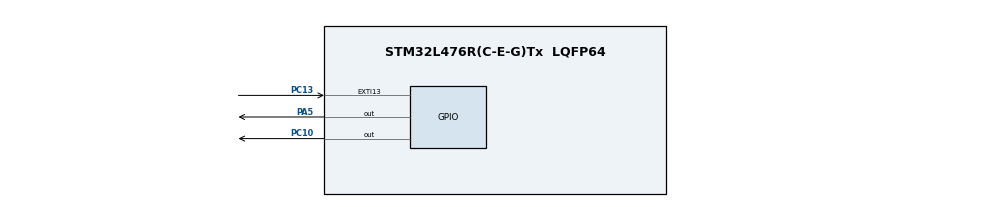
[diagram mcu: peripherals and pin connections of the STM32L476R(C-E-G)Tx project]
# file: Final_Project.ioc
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Mcu.Family=STM32L4
Mcu.Name=STM32L476R(C-E-G)Tx
Mcu.Package=LQFP64
NVIC.EXTI15_10_IRQn=true\:1\:0\:true\:false\:true\:true\:true
NVIC.PriorityGroup=NVIC_PRIORITYGROUP_4
PA5.Signal=GPIO_Output
PC10.Signal=GPIO_Output
PC13.GPIO_ModeDefaultEXTI=GPIO_MODE_IT_FALLING
PC13.Signal=GPXTI13
ProjectManager.HeapSize=0x200
ProjectManager.StackSize=0x400
ProjectManager.TargetToolchain=STM32CubeIDE
RCC.ADCFreq_Value=96000000
RCC.AHBFreq_Value=24000000
RCC.APB1Freq_Value=24000000
RCC.APB1TimFreq_Value=24000000
RCC.APB2Freq_Value=24000000
RCC.APB2TimFreq_Value=24000000
RCC.CortexFreq_Value=24000000
RCC.HCLKFreq_Value=24000000
RCC.HSE_VALUE=8000000
RCC.HSI_VALUE=16000000
RCC.LSE_VALUE=32768
RCC.MSIClockRange=RCC_MSIRANGE_9
RCC.MSI_VALUE=24000000
RCC.SYSCLKFreq_VALUE=24000000
RCC.USBFreq_Value=96000000
RCC.VCOOutputFreq_Value=192000000
VP_RTC_VS_RTC_Activate.Mode=RTC_Enabled
VP_RTC_VS_RTC_Calendar.Mode=RTC_Calendar
board=custom

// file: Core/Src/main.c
/* USER CODE BEGIN Header */
/**
  ******************************************************************************
  * @file           : main.c
  * @brief          : Main program body
  ******************************************************************************
  * @attention
  *
  * <h2><center>&copy; Copyright (c) 2020 STMicroelectronics.
  * All rights reserved.</center></h2>
  *
  * This software component is licensed by ST under BSD 3-Clause license,
  * the "License"; You may not use this file except in compliance with the
  * License. You may obtain a copy of the License at:
  *                        opensource.org/licenses/BSD-3-Clause
  *
  ******************************************************************************
  */
/* USER CODE END Header */
#include "main.h"
#include "rtc.h"
#include "gpio.h"

/* USER CODE BEGIN Includes */
#include "stdbool.h"
/* USER CODE END Includes */

/* USER CODE BEGIN PTD */
//Type d'actions pouvant être effectuées à l'activation du blue mode
typedef enum
{
	BLUE_MODE_ACTIVATE_SLEEP,        /*< Activation du sleep lors du passage en blue mode. */
	BLUE_MODE_ACTIVATE_CALIBRATION,  /*< Activation de la calibration lors du passage en blue mode. */
	BLUE_MODE_ACTIVATE_STOP,		 /*< Activation du stop lors du passage en blue mode. */
}blue_mode_t;
/* USER CODE END PTD */

/* USER CODE BEGIN PD */
//Configurations des clocks
#define CK_CONFIG_PLL_80MGHZ 0		/*< Configuration clock experience 1 (PLL 80MHz; MSI 4 MGHz). */
#define CK_CONFIG_MSI_24MGHZ 1		/*< Configuration clock autres experiences (MSI 24 MHz). */

//Configuration de la calibration
#define CALIBRATION_OFF 0			/*< calbration off en normal mode. */
#define CALIBRATION_ON 1			/*< calbration on en normal mode. */

//Configuration du sleep
#define SLEEP_OFF 0					/*< sleep(100Hz) off en normal mode. */
#define SLEEP_ON 1					/*< sleep(100Hz) on en normal mode. */

//Mode de fonctionnement du système
#define NORMAL_MODE 0				/*< mode normal. */
#define BLUE_MODE 1					/*< blue mode. */
/* USER CODE END PD */

/* USER CODE BEGIN PV */
int expe=1; 						/*< Numéro de l'expérience en cours. */
int compteur_systick=0;				/*< Compteur permettant de compter via l'interruption systick (pour le clignotement de la LED). */
int mode=NORMAL_MODE;				/*< Initialisation mode de fonctionnement en "normal". */
blue_mode_t blue_mode_action;		/*< Action à effectuer lors du blue mode. */
/* USER CODE END PV */

void SystemClock_Config(bool ck_config, uint32_t flash_latency,uint32_t voltage_scaling,bool calibration); //Fonction d'initialisation des clocks.
/* USER CODE BEGIN PFP */
void Systick_Init (void);                                      /*<Initialisation de systick. */
void LSE_Init(void);										   /*<Initialisation du LSE. */
void PLL_Activate(void);									   /*<Activation de la PLL. */
void PLL_Disable(void);                                        /*<Désactivation de la PLL. */
void RTC_wakeup_init_from_standby_or_shutdown( int delay );	   /*<Initialisation du réveil du mode shutdown. */
void RTC_wakeup_init_from_stop( int delay );                   /*<Initialisation du réveil des modes stop. */
/* USER CODE END PFP */

int main(void)
{
  /* USER CODE BEGIN 1 */
  //Paramètres des experiences
  bool ck_config;							/*< Configuration de la clock. */
  uint32_t flash_latency;                   /*< Configuration de la flash latency. */
  uint32_t voltage_scaling;					/*< Configuration du voltage scaling */
  bool calibration;							/*< Configuration calibration*/
  bool sleep;							    /*< Configuration du sleep */
  uint32_t stop;							/*< Configuration du "niveau de stp" (exp. 5 à 8) */
  /* USER CODE END 1 */

  /* MCU Configuration--------------------------------------------------------*/

  /* Reset of all peripherals, Initializes the Flash interface and the Systick. */

  LL_APB2_GRP1_EnableClock(LL_APB2_GRP1_PERIPH_SYSCFG);
  LL_APB1_GRP1_EnableClock(LL_APB1_GRP1_PERIPH_PWR);

  NVIC_SetPriorityGrouping(NVIC_PRIORITYGROUP_4);

  /* System interrupt init*/

  /* USER CODE BEGIN Init */
  //Initialisation LSE et RTC uniquement lors d'un démarrage à froid
  if(LL_RCC_LSE_IsReady() != 1)
     {
   	  LSE_Init();
   	  MX_RTC_Init();
     }

  //Récupération expe dans Bckup domain et incrémentation
   LL_APB1_GRP1_EnableClock( LL_APB1_GRP1_PERIPH_PWR );
   LL_PWR_EnableBkUpAccess();
   LL_RTC_DisableWriteProtection(RTC);
   expe=LL_RTC_BAK_GetRegister(RTC, 0)+1;
   if (expe==9)
   {
	   expe=1;
	   LL_RTC_BAK_SetRegister(RTC, 0, 0);
   }
   else
   {
	   LL_RTC_BAK_SetRegister(RTC, 0, expe);
   }
   LL_RTC_EnableWriteProtection(RTC);

  //Définition des paramètres de chaque experience selon la valeur de expe
    switch(expe)
    {
    case 1:
  	  ck_config=CK_CONFIG_PLL_80MGHZ;
  	  flash_latency=LL_FLASH_LATENCY_4;
  	  voltage_scaling=LL_PWR_REGU_VOLTAGE_SCALE1;
  	  calibration=CALIBRATION_OFF;
  	  sleep=SLEEP_OFF;
  	  blue_mode_action=BLUE_MODE_ACTIVATE_SLEEP;
  	  break;
    case 2:
  	  ck_config=CK_CONFIG_MSI_24MGHZ;
  	  flash_latency=LL_FLASH_LATENCY_1;
  	  voltage_scaling=LL_PWR_REGU_VOLTAGE_SCALE1;
  	  calibration=CALIBRATION_OFF;
  	  sleep=SLEEP_OFF;
  	  blue_mode_action=BLUE_MODE_ACTIVATE_CALIBRATION;
  	  break;
    case 3:
      ck_config=CK_CONFIG_MSI_24MGHZ;
      flash_latency=LL_FLASH_LATENCY_3;
      voltage_scaling=LL_PWR_REGU_VOLTAGE_SCALE2;
      calibration=CALIBRATION_OFF;
      sleep=SLEEP_OFF;
      blue_mode_action=BLUE_MODE_ACTIVATE_SLEEP;
      break;
    case 4:
      ck_config=CK_CONFIG_MSI_24MGHZ;
      flash_latency=LL_FLASH_LATENCY_3;
      voltage_scaling=LL_PWR_REGU_VOLTAGE_SCALE2;
      calibration=CALIBRATION_OFF;
      sleep=SLEEP_OFF;
      blue_mode_action=BLUE_MODE_ACTIVATE_CALIBRATION;
      break;
    case 5:
  	  ck_config=CK_CONFIG_MSI_24MGHZ;
  	  flash_latency=LL_FLASH_LATENCY_3;
  	  voltage_scaling=LL_PWR_REGU_VOLTAGE_SCALE2;
  	  calibration=CALIBRATION_ON;
  	  sleep=SLEEP_ON;
  	  stop=LL_PWR_MODE_STOP0;
  	  blue_mode_action=BLUE_MODE_ACTIVATE_STOP;
  	  break;
    case 6:
      ck_config=CK_CONFIG_MSI_24MGHZ;
      flash_latency=LL_FLASH_LATENCY_3;
  	  voltage_scaling=LL_PWR_REGU_VOLTAGE_SCALE2;
  	  calibration=CALIBRATION_ON;
      sleep=SLEEP_ON;
   	  stop=LL_PWR_MODE_STOP1;
   	  blue_mode_action=BLUE_MODE_ACTIVATE_STOP;
   	  break;
    case 7:
      ck_config=CK_CONFIG_MSI_24MGHZ;
      flash_latency=LL_FLASH_LATENCY_3;
      voltage_scaling=LL_PWR_REGU_VOLTAGE_SCALE2;
      calibration=CALIBRATION_ON;
      sleep=SLEEP_ON;
      stop=LL_PWR_MODE_STOP2;
      blue_mode_action=BLUE_MODE_ACTIVATE_STOP;
      break;
    case 8:
      ck_config=CK_CONFIG_MSI_24MGHZ;
      flash_latency=LL_FLASH_LATENCY_3;
      voltage_scaling=LL_PWR_REGU_VOLTAGE_SCALE2;
  	  calibration=CALIBRATION_ON;
      sleep=SLEEP_ON;
      stop=LL_PWR_MODE_SHUTDOWN;
   	  blue_mode_action=BLUE_MODE_ACTIVATE_STOP;
   	  break;
    }
  /* USER CODE END Init */

  /* Configure the system clock */
  SystemClock_Config(ck_config,flash_latency,voltage_scaling,calibration);

  /* USER CODE BEGIN SysInit */
  //Initialisation systick
  Systick_Init ();
  /* USER CODE END SysInit */

  /* Initialize all configured peripherals */
  MX_GPIO_Init();

  /* Infinite loop */
  while (1)
  {

    /* USER CODE BEGIN 3 */
	  //Activation du sleep en blue mode OU lorsque le sleep est activé en normal mode (exp. 5 à8)
	  if (((sleep==SLEEP_ON)&&(mode==NORMAL_MODE))||((mode==BLUE_MODE)&&(blue_mode_action==BLUE_MODE_ACTIVATE_SLEEP)))
	    {
		  LL_LPM_EnableSleep();
		  __WFI();
	    }
	  //Activation du stop en blue mode
	  if ((mode==BLUE_MODE)&&(blue_mode_action==BLUE_MODE_ACTIVATE_STOP))
	  	{
		  	mode=NORMAL_MODE;
	  		LL_PWR_SetPowerMode(stop);
	  		if (stop==LL_PWR_MODE_SHUTDOWN) //cas shutdown (exp 8)
	  			RTC_wakeup_init_from_standby_or_shutdown(10);
	  		else //cas stop (exp 5 à 8)
	  			RTC_wakeup_init_from_stop(10);

	  		LL_LPM_EnableDeepSleep();
	  		__WFI();
	  	}
  }
  /* USER CODE END 3 */
}

void SystemClock_Config(bool ck_config, uint32_t flash_latency,uint32_t voltage_scaling,bool calibration)
{
  //Gestion flash latency et voltage scaling
  LL_FLASH_SetLatency(flash_latency);
  while(LL_FLASH_GetLatency()!= flash_latency)
  {
  }
  LL_PWR_SetRegulVoltageScaling(voltage_scaling);
  LL_RCC_MSI_Enable();

   /* Wait till MSI is ready */
  while(LL_RCC_MSI_IsReady() != 1)
  {

  }
  LL_RCC_MSI_EnableRangeSelection();
  //Gestion fréquence de clock et PLL
    if(ck_config==CK_CONFIG_MSI_24MGHZ){ //Cas MSI à 24MHz sans PLL
  	  LL_RCC_MSI_SetRange(LL_RCC_MSIRANGE_9);
  	 /* Wait till System clock is ready */
  	  while(LL_RCC_GetSysClkSource() != LL_RCC_SYS_CLKSOURCE_STATUS_MSI)
  	  {

  	  }
  	  LL_RCC_SetAHBPrescaler(LL_RCC_SYSCLK_DIV_1);
  	  LL_RCC_SetAPB1Prescaler(LL_RCC_APB1_DIV_1);
  	  LL_RCC_SetAPB2Prescaler(LL_RCC_APB2_DIV_1);

  	  LL_Init1msTick(24000000);

  	  LL_SetSystemCoreClock(24000000);
    }else{								//Cas MSI 4Mhz et PLL à 80MHz
  	  LL_RCC_MSI_SetRange(LL_RCC_MSIRANGE_6);
  	  LL_RCC_MSI_SetCalibTrimming(0);
  	  LL_RCC_PLL_ConfigDomain_SYS(LL_RCC_PLLSOURCE_MSI, LL_RCC_PLLM_DIV_1, 40, LL_RCC_PLLR_DIV_2);
  	  LL_RCC_PLL_EnableDomain_SYS();
  	  LL_RCC_PLL_Enable();
  	/* Wait till PLL is ready */
  	  while(LL_RCC_PLL_IsReady() != 1)
  	  {

  	  }
  	  LL_RCC_SetSysClkSource(LL_RCC_SYS_CLKSOURCE_PLL);

  	   /* Wait till System clock is ready */
  	  while(LL_RCC_GetSysClkSource() != LL_RCC_SYS_CLKSOURCE_STATUS_PLL)
  	  {

  	  }
  	  LL_RCC_SetAHBPrescaler(LL_RCC_SYSCLK_DIV_1);
  	  LL_RCC_SetAPB1Prescaler(LL_RCC_APB1_DIV_1);
  	  LL_RCC_SetAPB2Prescaler(LL_RCC_APB2_DIV_1);

  	  LL_Init1msTick(80000000);

  	  LL_SetSystemCoreClock(80000000);
    }
    //Gestion Calibration
    if(calibration==CALIBRATION_ON){
    	PLL_Activate();
    }
    else{
    	PLL_Disable();
    }
}

/* USER CODE BEGIN 4 */
void Systick_Init (void)
{
	int clock=0;
	SysTick->CTRL |= (1<<2);
	SysTick->CTRL |= (1<<1);
	SystemCoreClockUpdate();
	clock=SystemCoreClock/100;
	SysTick->LOAD = clock;//SystemCoreClock/100;
	SysTick->VAL=0;
	NVIC_SetPriority(-1,0);
	SysTick->CTRL |= (1<<0);
}

void LSE_Init(void)
{
	  LL_APB1_GRP1_EnableClock( LL_APB1_GRP1_PERIPH_PWR );
	  LL_PWR_EnableBkUpAccess();
	    /* Wait till LSE is ready */
	   if(LL_RCC_LSE_IsReady() != 1)
	   {
		   LL_RCC_ForceBackupDomainReset();
		   LL_RCC_ReleaseBackupDomainReset();
		   LL_RCC_LSE_SetDriveCapability(LL_RCC_LSEDRIVE_LOW);
		   LL_RCC_LSE_Enable();
		   while (LL_RCC_LSE_IsReady() != 1)
		   {

		   }
		   LL_RCC_SetRTCClockSource(LL_RCC_RTC_CLKSOURCE_LSE);
	   }
}

void SysTick_Handler(void)
//Interruption de systick (50Hz)
{
  compteur_systick++;
  if (compteur_systick==200) //clignotement de la LED tte les 2s
  {
	  LL_GPIO_TogglePin(GPIOA, LL_GPIO_PIN_5);
  }
  else if (compteur_systick==(200+expe*50)) //Durée d'impulsion dépendant de expe
  {
	  LL_GPIO_TogglePin(GPIOA, LL_GPIO_PIN_5);
	  compteur_systick=0;
  }
  LL_GPIO_TogglePin(GPIOC, LL_GPIO_PIN_10); //Génération signal carré sur PC10
}

void EXTI15_10_IRQHandler(void)
//Interruption bouton blue mode
{
  /* USER CODE BEGIN EXTI15_10_IRQn 0 */

  /* USER CODE END EXTI15_10_IRQn 0 */
  if (LL_EXTI_IsActiveFlag_0_31(LL_EXTI_LINE_13) != RESET)
  {
    LL_EXTI_ClearFlag_0_31(LL_EXTI_LINE_13);
    /* USER CODE BEGIN LL_EXTI_LINE_13 */
    mode=BLUE_MODE; //Passage en blue mode + gestion passage en calibration ON
    if (blue_mode_action==BLUE_MODE_ACTIVATE_CALIBRATION)
    {
    	PLL_Activate();
    }
    /* USER CODE END LL_EXTI_LINE_13 */
  }
  /* USER CODE BEGIN EXTI15_10_IRQn 1 */

  /* USER CODE END EXTI15_10_IRQn 1 */
}

void PLL_Activate(void)
{
	LL_RCC_MSI_EnablePLLMode();
	while(LL_RCC_MSI_IsReady() != 1)
   {

	}
	LL_RCC_MSI_SetCalibTrimming(0);
	LL_RCC_SetSysClkSource(LL_RCC_SYS_CLKSOURCE_MSI);
}

void PLL_Disable(void)
{
	LL_RCC_MSI_DisablePLLMode();
}
// partie commune a toutes les utilisations du wakeup timer
static void RTC_wakeup_init( int delay )
{
LL_RTC_DisableWriteProtection( RTC );
LL_RTC_WAKEUP_Disable( RTC );
while	( !LL_RTC_IsActiveFlag_WUTW( RTC ) )
	{ }
// connecter le timer a l'horloge 1Hz de la RTC
LL_RTC_WAKEUP_SetClock( RTC, LL_RTC_WAKEUPCLOCK_CKSPRE );
// fixer la duree de temporisation
LL_RTC_WAKEUP_SetAutoReload( RTC, delay );	// 16 bits
LL_RTC_ClearFlag_WUT(RTC);
LL_RTC_EnableIT_WUT(RTC);
LL_RTC_WAKEUP_Enable(RTC);
LL_RTC_EnableWriteProtection(RTC);
}

// Dans le cas des modes STANDBY et SHUTDOWN, le MPU sera reveille par reset
// causé par 1 wakeup line (interne ou externe) (le NVIC n'est plus alimenté)
void RTC_wakeup_init_from_standby_or_shutdown( int delay )
{
RTC_wakeup_init( delay );
// enable the Internal Wake-up line
LL_PWR_EnableInternWU();	// ceci ne concerne que Standby et Shutdown, pas STOPx
}

// Dans le cas des modes STOPx, le MPU sera reveille par interruption
// le module EXTI et une partie du NVIC sont encore alimentes
// le contenu de la RAM et des registres étant préservé, le MPU
// reprend l'execution après l'instruction WFI
void RTC_wakeup_init_from_stop( int delay )
{
RTC_wakeup_init( delay );
// valider l'interrupt par la ligne 20 du module EXTI, qui est réservée au wakeup timer
LL_EXTI_EnableIT_0_31( LL_EXTI_LINE_20 );
LL_EXTI_EnableRisingTrig_0_31( LL_EXTI_LINE_20 );
// valider l'interrupt chez NVIC
NVIC_SetPriority( RTC_WKUP_IRQn, 1 );
NVIC_EnableIRQ( RTC_WKUP_IRQn );
}

// wakeup timer interrupt Handler (inutile mais doit etre defini)
void RTC_WKUP_IRQHandler()
{
LL_EXTI_ClearFlag_0_31( LL_EXTI_LINE_20 );
}
/* USER CODE END 4 */

void Error_Handler(void)
{
}

/************************ (C) COPYRIGHT STMicroelectronics *****END OF FILE****/
